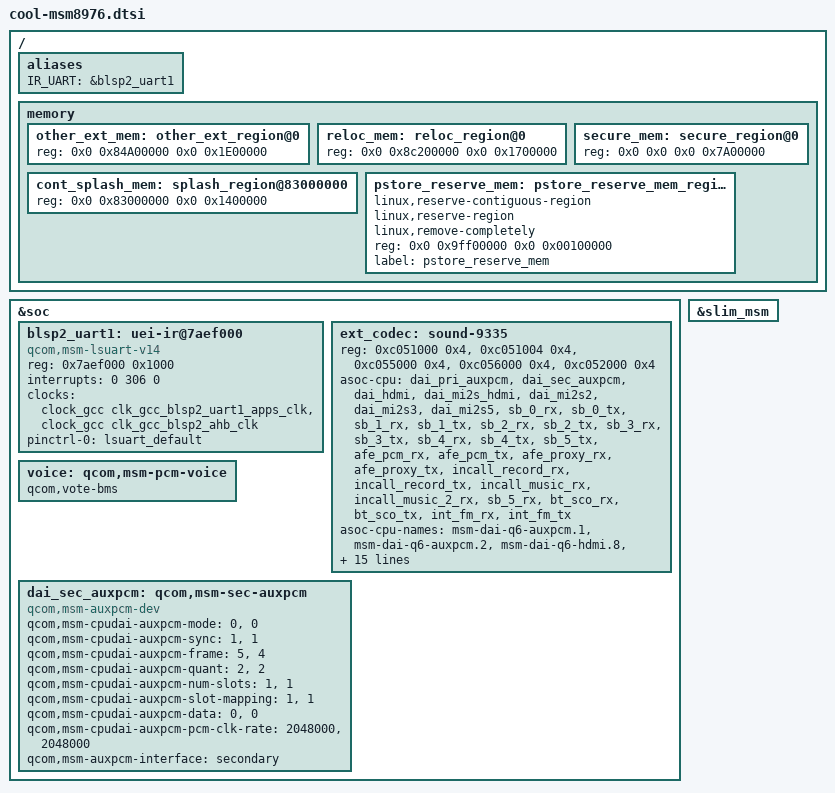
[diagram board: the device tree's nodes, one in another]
/*
 * Copyright (c) 2014-2016, The Linux Foundation. All rights reserved.
 *
 * This program is free software; you can redistribute it and/or modify
 * it under the terms of the GNU General Public License version 2 and
 * only version 2 as published by the Free Software Foundation.
 *
 * This program is distributed in the hope that it will be useful,
 * but WITHOUT ANY WARRANTY; without even the implied warranty of
 * MERCHANTABILITY or FITNESS FOR A PARTICULAR PURPOSE.  See the
 * GNU General Public License for more details.
 */

/ {

	aliases {
		/*yuong add for UEI remoteir 20160406*/
		IR_UART = &blsp2_uart1;
		/*yulong end*/
	};
       
	memory {

		other_ext_mem: other_ext_region@0 {
			reg = <0x0 0x84A00000 0x0 0x1E00000>;
		};

		reloc_mem: reloc_region@0 {
			reg = <0x0 0x8c200000 0x0 0x1700000>;
		};

		secure_mem: secure_region@0 {
			reg = <0x0 0x0 0x0 0x7A00000>;
		};

		cont_splash_mem: splash_region@83000000 {
			reg = <0x0 0x83000000 0x0 0x1400000>;
		};

		pstore_reserve_mem: pstore_reserve_mem_region@0 {
			linux,reserve-contiguous-region;
			linux,reserve-region;
			linux,remove-completely;
			/*< LAFITE-3550 liumaoxin 20160302 start>*/
			reg = <0x0 0x9ff00000 0x0 0x00100000>;
			/*< LAFITE-3550 liumaoxin 20160302 end>*/
			label = "pstore_reserve_mem";
		};
	};
};

&soc {

	/*yulong add for UEI remoteir 20160406*/
	blsp2_uart1: uei-ir@7aef000 {
		compatible = "qcom,msm-lsuart-v14";
		reg = <0x7aef000 0x1000>;
		interrupts = <0 306 0>;
		status = "ok";
		clock-names = "core_clk", "iface_clk";
		clocks = <&clock_gcc clk_gcc_blsp2_uart1_apps_clk>,
			<&clock_gcc clk_gcc_blsp2_ahb_clk>;
		pinctrl-names = "default";
		pinctrl-0 = <&lsuart_default>;
	};
	/*yulong add end*/

	ext_codec: sound-9335 {
		reg = <0xc051000 0x4>,
		    <0xc051004 0x4>,
		    <0xc055000 0x4>,
		    <0xc056000 0x4>,
		    <0xc052000 0x4>;

		reg-names = "csr_gp_io_mux_mic_ctl",
			"csr_gp_io_mux_spkr_ctl",
			"csr_gp_io_lpaif_pri_pcm_pri_mode_muxsel",
			"csr_gp_io_lpaif_sec_pcm_sec_mode_muxsel",
			"csr_gp_io_mux_quin_ctl";

		asoc-cpu = <&dai_pri_auxpcm>, <&dai_sec_auxpcm>, <&dai_hdmi>,
				<&dai_mi2s_hdmi>,
				<&dai_mi2s2>, <&dai_mi2s3>, <&dai_mi2s5>,
				<&sb_0_rx>, <&sb_0_tx>, <&sb_1_rx>, <&sb_1_tx>,
				<&sb_2_rx>, <&sb_2_tx>, <&sb_3_rx>, <&sb_3_tx>,
				<&sb_4_rx>, <&sb_4_tx>, <&sb_5_tx>, <&afe_pcm_rx>,
				<&afe_pcm_tx>, <&afe_proxy_rx>, <&afe_proxy_tx>,
				<&incall_record_rx>, <&incall_record_tx>,
				<&incall_music_rx>, <&incall_music_2_rx>,
				<&sb_5_rx>,  <&bt_sco_rx>,
				<&bt_sco_tx>, <&int_fm_rx>, <&int_fm_tx>;
		asoc-cpu-names = "msm-dai-q6-auxpcm.1", "msm-dai-q6-auxpcm.2",
				"msm-dai-q6-hdmi.8",
				"msm-dai-q6-mi2s-hdmi.4118",
				"msm-dai-q6-mi2s.2",
				"msm-dai-q6-mi2s.3", "msm-dai-q6-mi2s.5",
				"msm-dai-q6-dev.16384", "msm-dai-q6-dev.16385",
				"msm-dai-q6-dev.16386", "msm-dai-q6-dev.16387",
				"msm-dai-q6-dev.16388", "msm-dai-q6-dev.16389",
				"msm-dai-q6-dev.16390", "msm-dai-q6-dev.16391",
				"msm-dai-q6-dev.16392", "msm-dai-q6-dev.16393",
				"msm-dai-q6-dev.16395", "msm-dai-q6-dev.224",
				"msm-dai-q6-dev.225", "msm-dai-q6-dev.241",
				"msm-dai-q6-dev.240", "msm-dai-q6-dev.32771",
				"msm-dai-q6-dev.32772", "msm-dai-q6-dev.32773",
				"msm-dai-q6-dev.32770", "msm-dai-q6-dev.16394",
				"msm-dai-q6-dev.12288", "msm-dai-q6-dev.12289",
				"msm-dai-q6-dev.12292", "msm-dai-q6-dev.12293";
	};

	voice: qcom,msm-pcm-voice {
		qcom,vote-bms;
	};

	dai_sec_auxpcm: qcom,msm-sec-auxpcm {
		compatible = "qcom,msm-auxpcm-dev";
		qcom,msm-cpudai-auxpcm-mode = <0>, <0>;
		qcom,msm-cpudai-auxpcm-sync = <1>, <1>;
		qcom,msm-cpudai-auxpcm-frame = <5>, <4>;
		qcom,msm-cpudai-auxpcm-quant = <2>, <2>;
		qcom,msm-cpudai-auxpcm-num-slots = <1>, <1>;
		qcom,msm-cpudai-auxpcm-slot-mapping = <1>, <1>;
		qcom,msm-cpudai-auxpcm-data = <0>, <0>;
		qcom,msm-cpudai-auxpcm-pcm-clk-rate = <2048000>, <2048000>;
		qcom,msm-auxpcm-interface = "secondary";
	};


	/delete-node/ audio_ext_clk;
};

&slim_msm {
	/delete-node/ tasha_codec;
};

